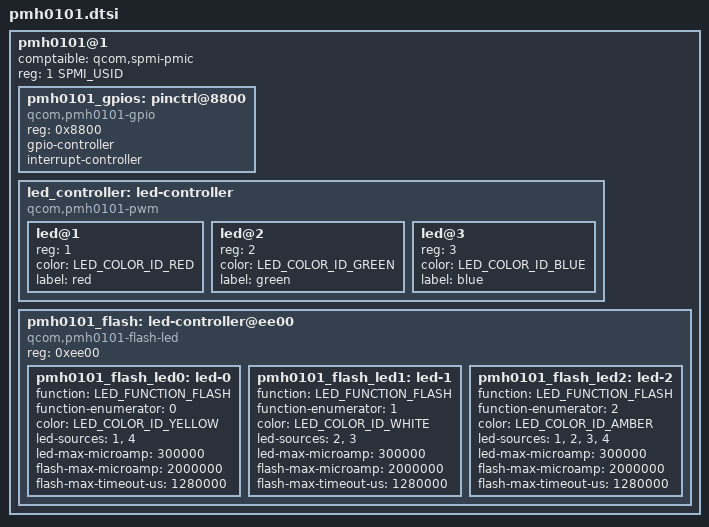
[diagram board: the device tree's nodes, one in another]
// SPDX-License-Identifier: BSD-3-Clause
/*
 * Copyright (c) 2024 Qualcomm Innovation Center, Inc. All rights reserved.
 */

#include <dt-bindings/leds/common.h>
#include <dt-bindings/spmi/spmi.h>

pmh0101@1 {
	comptaible = "qcom,spmi-pmic";
	reg = <1 SPMI_USID>;
	#address-cells = <1>;
	#size-cells = <0>;

	pmh0101_gpios: pinctrl@8800 {
		compatible = "qcom,pmh0101-gpio";
		reg = <0x8800>;
		gpio-controller;
		#gpio-cells = <2>;
		interrupt-controller;
		#interrupt-cells = <2>;
	};

	led_controller: led-controller {
		compatible = "qcom,pmh0101-pwm", "qcom,pm8350c-pwm";
		#address-cells = <1>;
		#size-cells = <0>;
		#pwm-cells = <2>;

		led@1 {
			reg = <1>;
			color = <LED_COLOR_ID_RED>;
			label = "red";
		};

		led@2 {
			reg = <2>;
			color = <LED_COLOR_ID_GREEN>;
			label = "green";
		};

		led@3 {
			reg = <3>;
			color = <LED_COLOR_ID_BLUE>;
			label = "blue";
		};
	};

	pmh0101_flash: led-controller@ee00 {
		compatible = "qcom,pmh0101-flash-led", "qcom,spmi-flash-led";
		reg = <0xee00>;

		pmh0101_flash_led0: led-0 {
			function = LED_FUNCTION_FLASH;
			function-enumerator = <0>;
			color = <LED_COLOR_ID_YELLOW>;
			led-sources = <1>, <4>;
			led-max-microamp = <300000>;
			flash-max-microamp = <2000000>;
			flash-max-timeout-us = <1280000>;
		};

		pmh0101_flash_led1: led-1 {
			function = LED_FUNCTION_FLASH;
			function-enumerator = <1>;
			color = <LED_COLOR_ID_WHITE>;
			led-sources = <2>, <3>;
			led-max-microamp = <300000>;
			flash-max-microamp = <2000000>;
			flash-max-timeout-us = <1280000>;
		};

		pmh0101_flash_led2: led-2 {
			function = LED_FUNCTION_FLASH;
			function-enumerator = <2>;
			color = <LED_COLOR_ID_AMBER>;
			led-sources = <1>, <2>, <3>, <4>;
			led-max-microamp = <300000>;
			flash-max-microamp = <2000000>;
			flash-max-timeout-us = <1280000>;
		};
	};
};
